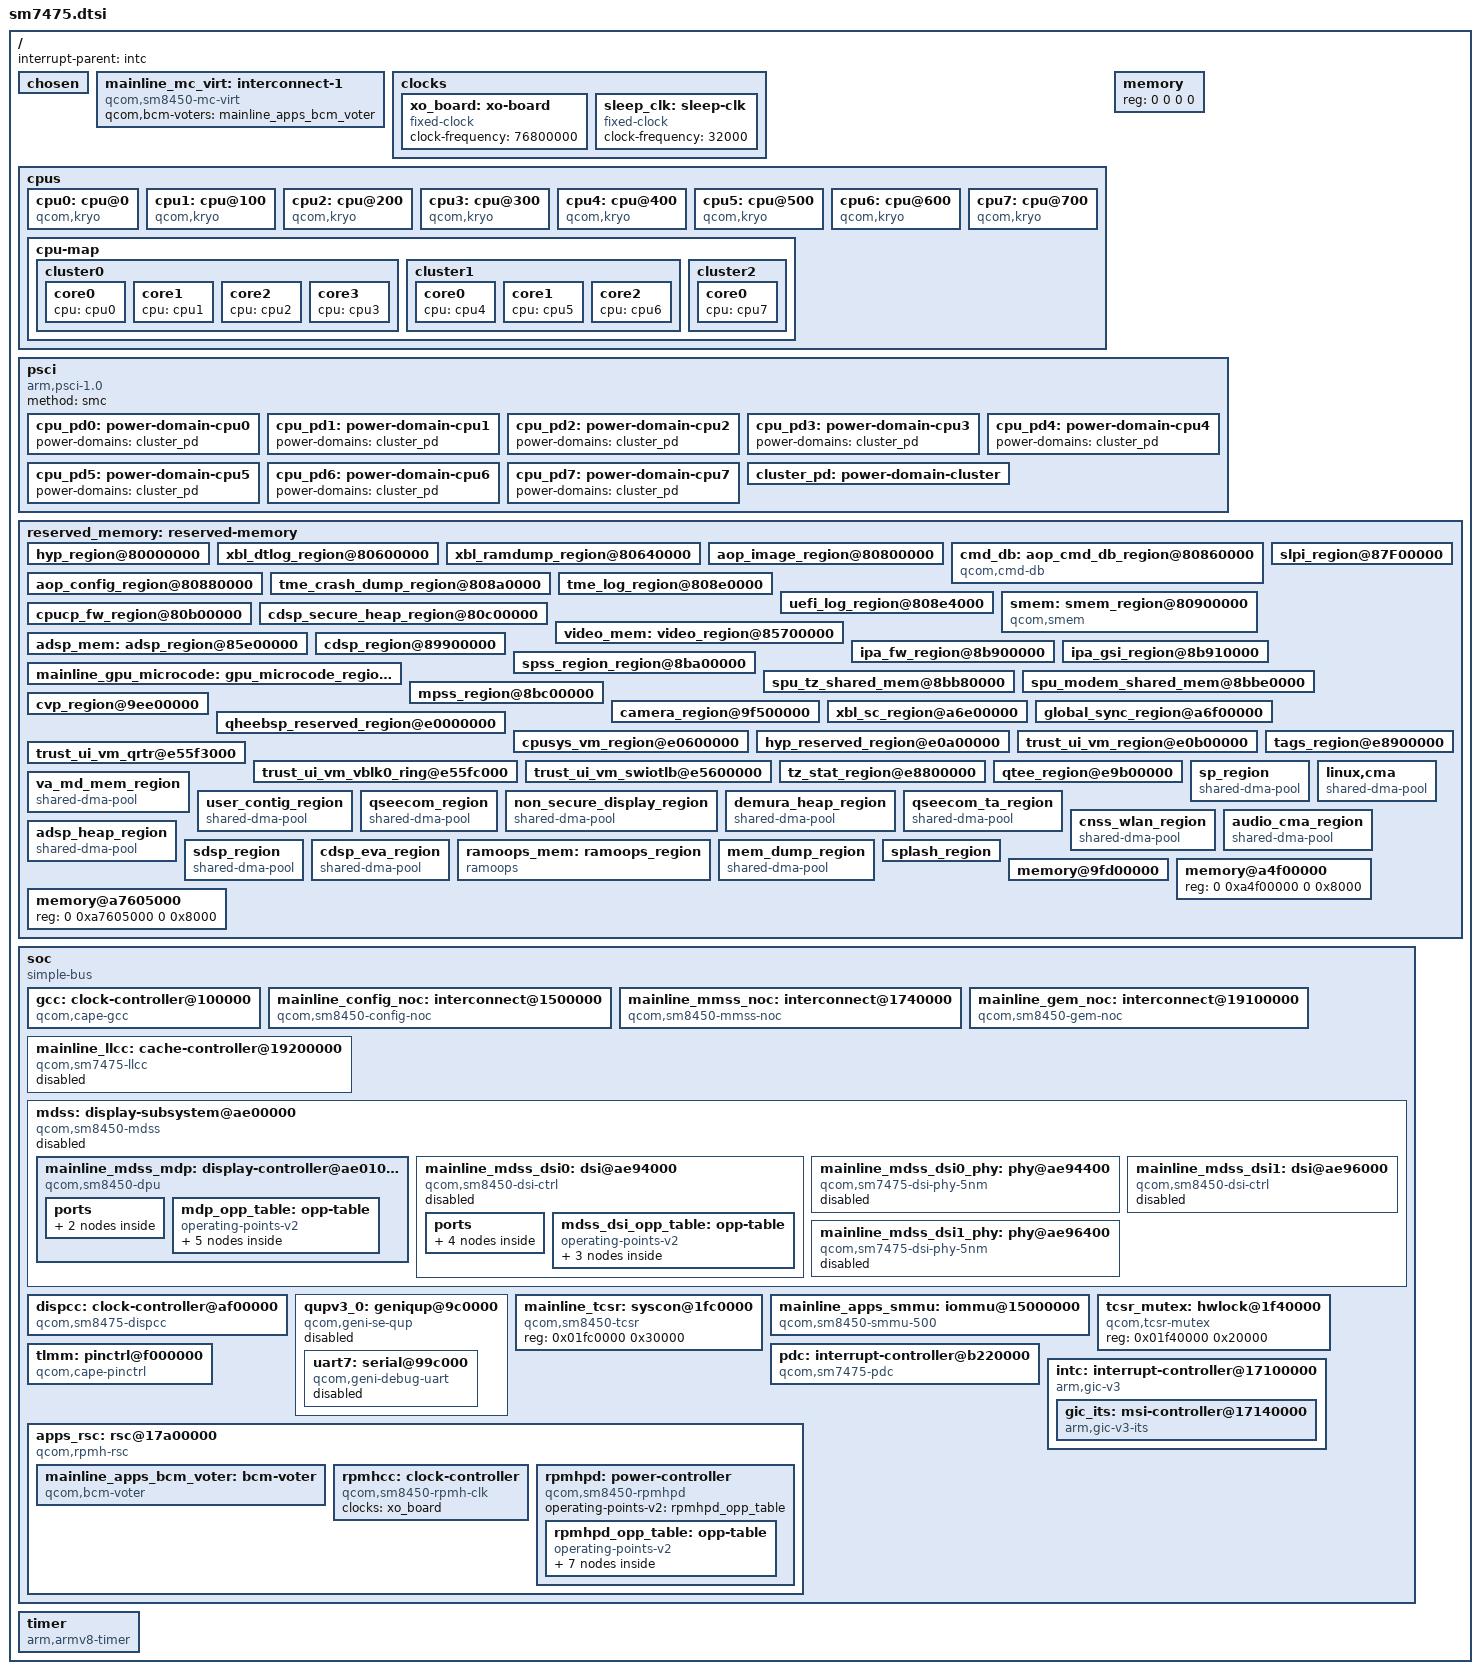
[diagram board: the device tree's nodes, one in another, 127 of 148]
// SPDX-License-Identifier: BSD-3-Clause

#include <dt-bindings/clock/qcom,sm7475-gcc.h>
#include <dt-bindings/clock/qcom,dsi-phy-28nm.h>
#include <dt-bindings/clock/qcom,sm8450-dispcc.h>
#include <dt-bindings/clock/qcom,rpmh.h>
#include <dt-bindings/interconnect/qcom,icc.h>
#include <dt-bindings/interconnect/qcom,sm8450.h>
#include <dt-bindings/interrupt-controller/arm-gic.h>
#include <dt-bindings/power/qcom,rpmhpd.h>
#include <dt-bindings/soc/qcom,rpmh-rsc.h>

/ {
	#address-cells = <2>;
	#size-cells = <2>;
	interrupt-parent = <&intc>;

	chosen { };

	mainline_mc_virt: interconnect-1 {
		compatible = "qcom,sm8450-mc-virt";
		#interconnect-cells = <2>;
		qcom,bcm-voters = <&mainline_apps_bcm_voter>;
	};

	clocks {
		xo_board: xo-board {
			compatible = "fixed-clock";
			#clock-cells = <0>;
			clock-frequency = <76800000>;
		};

		sleep_clk: sleep-clk {
			compatible = "fixed-clock";
			#clock-cells = <0>;
			clock-frequency = <32000>;
		};
	};

	cpus {
		#address-cells = <2>;
		#size-cells = <0>;

		cpu0: cpu@0 {
			compatible = "qcom,kryo";
			device_type = "cpu";
			reg = <0 0x000>;
			enable-method = "psci";
			power-domains = <&cpu_pd0>;
			power-domain-names = "psci";
		};

		cpu1: cpu@100 {
			compatible = "qcom,kryo";
			device_type = "cpu";
			reg = <0 0x100>;
			enable-method = "psci";
			power-domains = <&cpu_pd1>;
			power-domain-names = "psci";
		};

		cpu2: cpu@200 {
			compatible = "qcom,kryo";
			device_type = "cpu";
			reg = <0 0x200>;
			enable-method = "psci";
			power-domains = <&cpu_pd2>;
			power-domain-names = "psci";
		};

		cpu3: cpu@300 {
			compatible = "qcom,kryo";
			device_type = "cpu";
			reg = <0 0x300>;
			enable-method = "psci";
			power-domains = <&cpu_pd3>;
			power-domain-names = "psci";
		};

		cpu4: cpu@400 {
			compatible = "qcom,kryo";
			device_type = "cpu";
			reg = <0 0x400>;
			enable-method = "psci";
			power-domains = <&cpu_pd4>;
			power-domain-names = "psci";
		};

		cpu5: cpu@500 {
			compatible = "qcom,kryo";
			device_type = "cpu";
			reg = <0 0x500>;
			enable-method = "psci";
			power-domains = <&cpu_pd5>;
			power-domain-names = "psci";
		};

		cpu6: cpu@600 {
			compatible = "qcom,kryo";
			device_type = "cpu";
			reg = <0 0x600>;
			enable-method = "psci";
			power-domains = <&cpu_pd6>;
			power-domain-names = "psci";
		};

		cpu7: cpu@700 {
			compatible = "qcom,kryo";
			device_type = "cpu";
			reg = <0 0x700>;
			enable-method = "psci";
			power-domains = <&cpu_pd7>;
			power-domain-names = "psci";
		};

		cpu-map {
			cluster0 {
				core0 { cpu = <&cpu0>; };
				core1 { cpu = <&cpu1>; };
				core2 { cpu = <&cpu2>; };
				core3 { cpu = <&cpu3>; };
			};
			cluster1 {
				core0 { cpu = <&cpu4>; };
				core1 { cpu = <&cpu5>; };
				core2 { cpu = <&cpu6>; };
			};
			cluster2 {
				core0 { cpu = <&cpu7>; };
			};
		};
	};

	/* The Ukee bootloader fills the installed RAM banks. */
	memory {
		device_type = "memory";
		reg = <0 0 0 0>;
	};

	psci {
		compatible = "arm,psci-1.0";
		method = "smc";

		cpu_pd0: power-domain-cpu0 {
			#power-domain-cells = <0>;
			power-domains = <&cluster_pd>;
		};
		cpu_pd1: power-domain-cpu1 {
			#power-domain-cells = <0>;
			power-domains = <&cluster_pd>;
		};
		cpu_pd2: power-domain-cpu2 {
			#power-domain-cells = <0>;
			power-domains = <&cluster_pd>;
		};
		cpu_pd3: power-domain-cpu3 {
			#power-domain-cells = <0>;
			power-domains = <&cluster_pd>;
		};
		cpu_pd4: power-domain-cpu4 {
			#power-domain-cells = <0>;
			power-domains = <&cluster_pd>;
		};
		cpu_pd5: power-domain-cpu5 {
			#power-domain-cells = <0>;
			power-domains = <&cluster_pd>;
		};
		cpu_pd6: power-domain-cpu6 {
			#power-domain-cells = <0>;
			power-domains = <&cluster_pd>;
		};
		cpu_pd7: power-domain-cpu7 {
			#power-domain-cells = <0>;
			power-domains = <&cluster_pd>;
		};
		cluster_pd: power-domain-cluster {
			#power-domain-cells = <0>;
		};
	};

	reserved_memory: reserved-memory {
		#address-cells = <0x02>;
		#size-cells = <0x02>;
		ranges;
		hyp_region@80000000 {
			no-map;
			reg = <0x00 0x80000000 0x00 0x600000>;
		};
		xbl_dtlog_region@80600000 {
			no-map;
			reg = <0x00 0x80600000 0x00 0x40000>;
		};
		xbl_ramdump_region@80640000 {
			no-map;
			reg = <0x00 0x80640000 0x00 0x1c0000>;
		};
		aop_image_region@80800000 {
			no-map;
			reg = <0x00 0x80800000 0x00 0x60000>;
		};
		cmd_db: aop_cmd_db_region@80860000 {
			compatible = "qcom,cmd-db";
			no-map;
			reg = <0x00 0x80860000 0x00 0x20000>;
		};
		aop_config_region@80880000 {
			no-map;
			reg = <0x00 0x80880000 0x00 0x20000>;
		};
		tme_crash_dump_region@808a0000 {
			no-map;
			reg = <0x00 0x808a0000 0x00 0x40000>;
		};
		tme_log_region@808e0000 {
			no-map;
			reg = <0x00 0x808e0000 0x00 0x4000>;
		};
		uefi_log_region@808e4000 {
			no-map;
			reg = <0x00 0x808e4000 0x00 0x10000>;
		};
		smem: smem_region@80900000 {
			compatible = "qcom,smem";
			hwlocks = <&tcsr_mutex 3>;
			no-map;
			reg = <0x00 0x80900000 0x00 0x200000>;
		};
		cpucp_fw_region@80b00000 {
			no-map;
			reg = <0x00 0x80b00000 0x00 0x100000>;
		};
		cdsp_secure_heap_region@80c00000 {
			no-map;
			reg = <0x00 0x80c00000 0x00 0x100000>;
		};
		video_mem: video_region@85700000 {
			no-map;
			reg = <0x00 0x85700000 0x00 0x700000>;
		};
		adsp_mem: adsp_region@85e00000 {
			no-map;
			reg = <0x00 0x85e00000 0x00 0x2100000>;
		};
		slpi_region@87F00000 {
			no-map;
			reg = <0x00 0x87f00000 0x00 0x1a00000>;
		};
		cdsp_region@89900000 {
			no-map;
			reg = <0x00 0x89900000 0x00 0x2000000>;
		};
		ipa_fw_region@8b900000 {
			no-map;
			reg = <0x00 0x8b900000 0x00 0x10000>;
		};
		ipa_gsi_region@8b910000 {
			no-map;
			reg = <0x00 0x8b910000 0x00 0xa000>;
		};
		mainline_gpu_microcode: gpu_microcode_region@8b91a000 {
			no-map;
			reg = <0x00 0x8b91a000 0x00 0x2000>;
		};
		spss_region_region@8ba00000 {
			no-map;
			reg = <0x00 0x8ba00000 0x00 0x180000>;
		};
		spu_tz_shared_mem@8bb80000 {
			no-map;
			reg = <0x00 0x8bb80000 0x00 0x60000>;
		};
		spu_modem_shared_mem@8bbe0000 {
			no-map;
			reg = <0x00 0x8bbe0000 0x00 0x20000>;
		};
		mpss_region@8bc00000 {
			no-map;
			reg = <0x00 0x8bc00000 0x00 0x13200000>;
		};
		cvp_region@9ee00000 {
			no-map;
			reg = <0x00 0x9ee00000 0x00 0x700000>;
		};
		camera_region@9f500000 {
			no-map;
			reg = <0x00 0x9f500000 0x00 0x800000>;
		};
		xbl_sc_region@a6e00000 {
			no-map;
			reg = <0x00 0xa6e00000 0x00 0x40000>;
		};
		global_sync_region@a6f00000 {
			no-map;
			reg = <0x00 0xa6f00000 0x00 0x100000>;
		};
		qheebsp_reserved_region@e0000000 {
			no-map;
			reg = <0x00 0xe0000000 0x00 0x00>;
		};
		cpusys_vm_region@e0600000 {
			no-map;
			reg = <0x00 0xe0600000 0x00 0x400000>;
		};
		hyp_reserved_region@e0a00000 {
			no-map;
			reg = <0x00 0xe0a00000 0x00 0x100000>;
		};
		trust_ui_vm_region@e0b00000 {
			no-map;
			reg = <0x00 0xe0b00000 0x00 0x4af3000>;
		};
		trust_ui_vm_qrtr@e55f3000 {
			no-map;
			reg = <0x00 0xe55f3000 0x00 0x9000>;
		};
		trust_ui_vm_vblk0_ring@e55fc000 {
			no-map;
			reg = <0x00 0xe55fc000 0x00 0x4000>;
			gunyah-label = <0x11>;
		};
		trust_ui_vm_swiotlb@e5600000 {
			no-map;
			reg = <0x00 0xe5600000 0x00 0x100000>;
			gunyah-label = <0x12>;
		};
		tz_stat_region@e8800000 {
			no-map;
			reg = <0x00 0xe8800000 0x00 0x100000>;
		};
		tags_region@e8900000 {
			no-map;
			reg = <0x00 0xe8900000 0x00 0x1200000>;
		};
		qtee_region@e9b00000 {
			no-map;
			reg = <0x00 0xe9b00000 0x00 0x500000>;
		};
		sp_region {
			compatible = "shared-dma-pool";
			alloc-ranges = <0x00 0x00 0x00 0xffffffff>;
			reusable;
			alignment = <0x00 0x400000>;
			size = <0x00 0x1000000>;
		};
		linux,cma {
			compatible = "shared-dma-pool";
			alloc-ranges = <0x00 0x00 0x00 0xffffffff>;
			reusable;
			alignment = <0x00 0x400000>;
			size = <0x00 0x2000000>;
			linux,cma-default;
		};
		va_md_mem_region {
			compatible = "shared-dma-pool";
			alloc-ranges = <0x01 0x00 0xfffffffe 0xffffffff>;
			reusable;
			size = <0x00 0x1000000>;
		};
		user_contig_region {
			compatible = "shared-dma-pool";
			alloc-ranges = <0x00 0x00 0x00 0xffffffff>;
			reusable;
			alignment = <0x00 0x400000>;
			size = <0x00 0x1000000>;
		};
		qseecom_region {
			compatible = "shared-dma-pool";
			alloc-ranges = <0x00 0x00 0x00 0xffffffff>;
			reusable;
			alignment = <0x00 0x400000>;
			size = <0x00 0x4800000>;
		};
		non_secure_display_region {
			compatible = "shared-dma-pool";
			reusable;
			alloc-ranges = <0x00 0x00 0x00 0xffffffff>;
			size = <0x00 0xa400000>;
			alignment = <0x00 0x400000>;
		};
		demura_heap_region {
			compatible = "shared-dma-pool";
			reusable;
			alloc-ranges = <0x01 0x00 0xfffffffe 0xffffffff>;
			size = <0x00 0x2800000>;
			alignment = <0x00 0x400000>;
		};
		qseecom_ta_region {
			compatible = "shared-dma-pool";
			alloc-ranges = <0x00 0x00 0x00 0xffffffff>;
			reusable;
			alignment = <0x00 0x400000>;
			size = <0x00 0x1000000>;
		};
		cnss_wlan_region {
			compatible = "shared-dma-pool";
			alloc-ranges = <0x00 0x00 0x00 0xffffffff>;
			reusable;
			alignment = <0x00 0x400000>;
			size = <0x00 0x2000000>;
		};
		audio_cma_region {
			compatible = "shared-dma-pool";
			alloc-ranges = <0x00 0x00 0x00 0xffffffff>;
			reusable;
			alignment = <0x00 0x400000>;
			size = <0x00 0x1c00000>;
		};
		adsp_heap_region {
			compatible = "shared-dma-pool";
			alloc-ranges = <0x00 0x00 0x00 0xffffffff>;
			reusable;
			alignment = <0x00 0x400000>;
			size = <0x00 0xc00000>;
		};
		sdsp_region {
			compatible = "shared-dma-pool";
			alloc-ranges = <0x00 0x00 0x00 0xffffffff>;
			reusable;
			alignment = <0x00 0x400000>;
			size = <0x00 0x800000>;
		};
		cdsp_eva_region {
			compatible = "shared-dma-pool";
			alloc-ranges = <0x00 0x00 0x00 0xffffffff>;
			reusable;
			alignment = <0x00 0x400000>;
			size = <0x00 0x400000>;
		};
		ramoops_mem: ramoops_region {
			compatible = "ramoops";
			reg = <0x09 0x7a5c0000 0x00 0x00240000>;
			no-map;
			record-size = <0x00080000>;
			console-size = <0x00040000>;
			pmsg-size = <0x00040000>;
			mem-type = <0x02>;
		};
		mem_dump_region {
			compatible = "shared-dma-pool";
			alloc-ranges = <0x01 0x00 0xfffffffe 0xffffffff>;
			reusable;
			alignment = <0x00 0x400000>;
			size = <0x00 0x3000000>;
		};
		/* The bootloader leaves the panel scanout running here; keep it reserved. */
		splash_region {
			no-map;
			reg = <0x00 0xb8000000 0x00 0x2b00000>;
		};
		memory@9fd00000 { reg = <0 0x9fd00000 0 0x700000>; no-map; };
		memory@a4f00000 { reg = <0 0xa4f00000 0 0x8000>; };
		memory@a7605000 { reg = <0 0xa7605000 0 0x8000>; };
	};

	/* The stock base calls this node `soc` - the factory dtbo references that
	 * label - and addresses it with one cell per field (reg = <addr size>).
	 * The bootloader walks this node before the kernel runs, so keep both the
	 * name and the shape; the kernel derives addresses from the parent's cell
	 * count either way. */
	soc: soc {
		compatible = "simple-bus";
		#address-cells = <1>;
		#size-cells = <1>;
		ranges;

		/* Native Cape GCC support is required for the normal UART driver. */
		gcc: clock-controller@100000 {
			compatible = "qcom,cape-gcc";
			reg = <0x00100000 0x1f4200>;
			clocks = <&rpmhcc RPMH_CXO_CLK>, <&sleep_clk>;
			clock-names = "bi_tcxo", "sleep_clk";
			#clock-cells = <1>;
			#reset-cells = <1>;
			#power-domain-cells = <1>;
		};

		/* Waipio NoC resources and addresses match the stock SM7475 DTB. */
		mainline_config_noc: interconnect@1500000 {
			compatible = "qcom,sm8450-config-noc";
			reg = <0x01500000 0x1c000>;
			#interconnect-cells = <2>;
			qcom,bcm-voters = <&mainline_apps_bcm_voter>;
		};

		mainline_mmss_noc: interconnect@1740000 {
			compatible = "qcom,sm8450-mmss-noc";
			reg = <0x01740000 0x1f080>;
			#interconnect-cells = <2>;
			qcom,bcm-voters = <&mainline_apps_bcm_voter>;
		};

		mainline_gem_noc: interconnect@19100000 {
			compatible = "qcom,sm8450-gem-noc";
			reg = <0x19100000 0xbb800>;
			#interconnect-cells = <2>;
			qcom,bcm-voters = <&mainline_apps_bcm_voter>;
		};

		/* Ukee bank windows follow the stock LLCC v2.1 description. */
		mainline_llcc: cache-controller@19200000 {
			compatible = "qcom,sm7475-llcc";
			reg = <0x19200000 0x80000>,
			      <0x19600000 0x80000>,
			      <0x19300000 0x80000>,
			      <0x19700000 0x80000>,
			      <0x19a00000 0x80000>;
			reg-names = "llcc0_base", "llcc1_base", "llcc2_base",
				    "llcc3_base", "llcc_broadcast_base";
			status = "disabled";
		};

		/* Cape uses the SM8450 display register layout. */
		mdss: display-subsystem@ae00000 {
			compatible = "qcom,sm8450-mdss";
			reg = <0x0ae00000 0x1000>;
			reg-names = "mdss";
			/* Both display memory ports share the same Waipio path. */
			interconnects = <&mainline_mmss_noc MASTER_MDP_DISP 0
					 &mainline_mc_virt SLAVE_EBI1_DISP 0>,
					<&mainline_mmss_noc MASTER_MDP_DISP 0
					 &mainline_mc_virt SLAVE_EBI1_DISP 0>,
					<&mainline_gem_noc MASTER_APPSS_PROC
					 QCOM_ICC_TAG_ACTIVE_ONLY
					 &mainline_config_noc SLAVE_DISPLAY_CFG
					 QCOM_ICC_TAG_ACTIVE_ONLY>;
			interconnect-names = "mdp0-mem", "mdp1-mem", "cpu-cfg";
			resets = <&dispcc DISP_CC_MDSS_CORE_BCR>;
			clocks = <&dispcc DISP_CC_MDSS_AHB_CLK>,
				 <&gcc GCC_DISP_HF_AXI_CLK>,
				 <&gcc GCC_DISP_SF_AXI_CLK>,
				 <&dispcc DISP_CC_MDSS_MDP_CLK>;
			iommus = <&mainline_apps_smmu 0x2800 0x402>;
			interrupts = <GIC_SPI 83 IRQ_TYPE_LEVEL_HIGH>;
			interrupt-controller;
			#interrupt-cells = <1>;
			#address-cells = <1>;
			#size-cells = <1>;
			ranges;
			status = "disabled";

			mainline_mdss_mdp: display-controller@ae01000 {
				compatible = "qcom,sm8450-dpu";
				reg = <0x0ae01000 0x8f000>,
				      <0x0aeb0000 0x3000>;
				reg-names = "mdp", "vbif";
				clocks = <&gcc GCC_DISP_HF_AXI_CLK>,
					 <&gcc GCC_DISP_SF_AXI_CLK>,
					 <&dispcc DISP_CC_MDSS_AHB_CLK>,
					 <&dispcc DISP_CC_MDSS_MDP_LUT_CLK>,
					 <&dispcc DISP_CC_MDSS_MDP_CLK>,
					 <&dispcc DISP_CC_MDSS_VSYNC_CLK>;
				clock-names = "bus", "nrt_bus", "iface", "lut", "core", "vsync";
				assigned-clocks = <&dispcc DISP_CC_MDSS_VSYNC_CLK>;
				assigned-clock-rates = <19200000>;
				operating-points-v2 = <&mdp_opp_table>;
				power-domains = <&rpmhpd RPMHPD_MMCX>;
				interrupt-parent = <&mdss>;
				interrupts = <0>;
				ports {
					#address-cells = <1>;
					#size-cells = <0>;
					port@0 {
						reg = <0>;
						dpu_intf1_out: endpoint {
							remote-endpoint = <&mdss_dsi0_in>;
						};
					};
				};

				mdp_opp_table: opp-table {
					compatible = "operating-points-v2";

					opp-172000000 {
						opp-hz = /bits/ 64 <172000000>;
						required-opps = <&rpmhpd_opp_low_svs_d1>;
					};

					opp-200000000 {
						opp-hz = /bits/ 64 <200000000>;
						required-opps = <&rpmhpd_opp_low_svs>;
					};

					opp-325000000 {
						opp-hz = /bits/ 64 <325000000>;
						required-opps = <&rpmhpd_opp_svs>;
					};

					opp-375000000 {
						opp-hz = /bits/ 64 <375000000>;
						required-opps = <&rpmhpd_opp_svs_l1>;
					};

					opp-500000000 {
						opp-hz = /bits/ 64 <500000000>;
						required-opps = <&rpmhpd_opp_nom>;
					};
				};
			};

			mainline_mdss_dsi0: dsi@ae94000 {
				compatible = "qcom,sm8450-dsi-ctrl", "qcom,mdss-dsi-ctrl";
				reg = <0x0ae94000 0x400>;
				reg-names = "dsi_ctrl";
				interrupt-parent = <&mdss>;
				interrupts = <4>;
				clocks = <&dispcc DISP_CC_MDSS_BYTE0_CLK>,
					 <&dispcc DISP_CC_MDSS_BYTE0_INTF_CLK>,
					 <&dispcc DISP_CC_MDSS_PCLK0_CLK>,
					 <&dispcc DISP_CC_MDSS_ESC0_CLK>,
					 <&dispcc DISP_CC_MDSS_AHB_CLK>,
					 <&gcc GCC_DISP_HF_AXI_CLK>;
				clock-names = "byte", "byte_intf", "pixel", "core", "iface", "bus";
				assigned-clocks = <&dispcc DISP_CC_MDSS_BYTE0_CLK_SRC>,
						  <&dispcc DISP_CC_MDSS_PCLK0_CLK_SRC>;
				assigned-clock-parents = <&mainline_mdss_dsi0_phy DSI_BYTE_PLL_CLK>,
							 <&mainline_mdss_dsi0_phy DSI_PIXEL_PLL_CLK>;
				operating-points-v2 = <&mdss_dsi_opp_table>;
				power-domains = <&rpmhpd RPMHPD_MMCX>;
				phys = <&mainline_mdss_dsi0_phy>;
				phy-names = "dsi";
				#address-cells = <1>;
				#size-cells = <0>;
				status = "disabled";
				ports {
					#address-cells = <1>;
					#size-cells = <0>;
					port@0 {
						reg = <0>;
						mdss_dsi0_in: endpoint {
							remote-endpoint = <&dpu_intf1_out>;
						};
					};
					port@1 {
						reg = <1>;
						mdss_dsi0_out: endpoint {
						};
					};
				};

				mdss_dsi_opp_table: opp-table {
					compatible = "operating-points-v2";

					opp-187500000 {
						opp-hz = /bits/ 64 <187500000>;
						required-opps = <&rpmhpd_opp_low_svs>;
					};

					opp-300000000 {
						opp-hz = /bits/ 64 <300000000>;
						required-opps = <&rpmhpd_opp_svs>;
					};

					opp-358000000 {
						opp-hz = /bits/ 64 <358000000>;
						required-opps = <&rpmhpd_opp_svs_l1>;
					};
				};
			};

			mainline_mdss_dsi0_phy: phy@ae94400 {
				compatible = "qcom,sm7475-dsi-phy-5nm";
				reg = <0x0ae94400 0x200>, <0x0ae94600 0x280>,
				      <0x0ae94900 0x260>;
				reg-names = "dsi_phy", "dsi_phy_lane", "dsi_pll";
				#clock-cells = <1>;
				#phy-cells = <0>;
				clocks = <&dispcc DISP_CC_MDSS_AHB_CLK>, <&rpmhcc RPMH_CXO_CLK>;
				clock-names = "iface", "ref";
				status = "disabled";
			};

			mainline_mdss_dsi1: dsi@ae96000 {
				compatible = "qcom,sm8450-dsi-ctrl", "qcom,mdss-dsi-ctrl";
				reg = <0x0ae96000 0x400>;
				reg-names = "dsi_ctrl";
				interrupt-parent = <&mdss>;
				interrupts = <5>;
				clocks = <&dispcc DISP_CC_MDSS_BYTE1_CLK>,
					 <&dispcc DISP_CC_MDSS_BYTE1_INTF_CLK>,
					 <&dispcc DISP_CC_MDSS_PCLK1_CLK>,
					 <&dispcc DISP_CC_MDSS_ESC1_CLK>,
					 <&dispcc DISP_CC_MDSS_AHB_CLK>,
					 <&gcc GCC_DISP_HF_AXI_CLK>;
				clock-names = "byte", "byte_intf", "pixel", "core", "iface", "bus";
				assigned-clocks = <&dispcc DISP_CC_MDSS_BYTE1_CLK_SRC>,
						  <&dispcc DISP_CC_MDSS_PCLK1_CLK_SRC>;
				assigned-clock-parents = <&mainline_mdss_dsi1_phy DSI_BYTE_PLL_CLK>,
							 <&mainline_mdss_dsi1_phy DSI_PIXEL_PLL_CLK>;
				operating-points-v2 = <&mdss_dsi_opp_table>;
				power-domains = <&rpmhpd RPMHPD_MMCX>;
				phys = <&mainline_mdss_dsi1_phy>;
				phy-names = "dsi";
				#address-cells = <1>;
				#size-cells = <0>;
				status = "disabled";
			};

			mainline_mdss_dsi1_phy: phy@ae96400 {
				compatible = "qcom,sm7475-dsi-phy-5nm";
				reg = <0x0ae96400 0x200>, <0x0ae96600 0x280>,
				      <0x0ae96900 0x260>;
				reg-names = "dsi_phy", "dsi_phy_lane", "dsi_pll";
				#clock-cells = <1>;
				#phy-cells = <0>;
				clocks = <&dispcc DISP_CC_MDSS_AHB_CLK>, <&rpmhcc RPMH_CXO_CLK>;
				clock-names = "iface", "ref";
				status = "disabled";
			};
		};

		dispcc: clock-controller@af00000 {
			compatible = "qcom,sm8475-dispcc";
			reg = <0x0af00000 0x20000>;
			clocks = <&rpmhcc RPMH_CXO_CLK>, <&rpmhcc RPMH_CXO_CLK_A>,
				 <&gcc GCC_DISP_AHB_CLK>, <&sleep_clk>,
				 <&mainline_mdss_dsi0_phy DSI_BYTE_PLL_CLK>,
				 <&mainline_mdss_dsi0_phy DSI_PIXEL_PLL_CLK>,
				 <&mainline_mdss_dsi1_phy DSI_BYTE_PLL_CLK>,
				 <&mainline_mdss_dsi1_phy DSI_PIXEL_PLL_CLK>,
				 <0>, <0>, <0>, <0>, <0>, <0>, <0>, <0>;
			power-domains = <&rpmhpd RPMHPD_MMCX>;
			required-opps = <&rpmhpd_opp_low_svs>;
			#clock-cells = <1>;
			#reset-cells = <1>;
			#power-domain-cells = <1>;
			status = "okay";
		};

		qupv3_0: geniqup@9c0000 {
			compatible = "qcom,geni-se-qup";
			reg = <0x009c0000 0x2000>;
			clocks = <&gcc GCC_QUPV3_WRAP_0_M_AHB_CLK>,
				 <&gcc GCC_QUPV3_WRAP_0_S_AHB_CLK>;
			clock-names = "m-ahb", "s-ahb";
			/* SE payload DMA uses this stream; GPI rings use 0x5b6. */
			iommus = <&mainline_apps_smmu 0x5a3 0>;
			#address-cells = <2>;
			#size-cells = <2>;
			ranges;
			status = "disabled";

			uart7: serial@99c000 {
				compatible = "qcom,geni-debug-uart";
				reg = <0 0x0099c000 0 0x4000>;
				interrupts = <GIC_SPI 608 IRQ_TYPE_LEVEL_HIGH>;
				clocks = <&gcc GCC_QUPV3_WRAP0_S7_CLK>;
				clock-names = "se";
				status = "disabled";
			};
		};

		/* Keep factory overlay labels on their sinks; use private labels here. */
		mainline_tcsr: syscon@1fc0000 {
			compatible = "qcom,sm8450-tcsr", "syscon";
			reg = <0x01fc0000 0x30000>;
		};

		mainline_apps_smmu: iommu@15000000 {
			compatible = "qcom,sm8450-smmu-500", "qcom,smmu-500",
				     "arm,mmu-500";
			reg = <0x15000000 0x100000>;
			#iommu-cells = <2>;
			#global-interrupts = <1>;
			interrupts = <GIC_SPI 65 IRQ_TYPE_LEVEL_HIGH>,
				     <GIC_SPI 97 IRQ_TYPE_LEVEL_HIGH>,
				     <GIC_SPI 98 IRQ_TYPE_LEVEL_HIGH>,
				     <GIC_SPI 99 IRQ_TYPE_LEVEL_HIGH>,
				     <GIC_SPI 100 IRQ_TYPE_LEVEL_HIGH>,
				     <GIC_SPI 101 IRQ_TYPE_LEVEL_HIGH>,
				     <GIC_SPI 102 IRQ_TYPE_LEVEL_HIGH>,
				     <GIC_SPI 103 IRQ_TYPE_LEVEL_HIGH>,
				     <GIC_SPI 104 IRQ_TYPE_LEVEL_HIGH>,
				     <GIC_SPI 105 IRQ_TYPE_LEVEL_HIGH>,
				     <GIC_SPI 106 IRQ_TYPE_LEVEL_HIGH>,
				     <GIC_SPI 107 IRQ_TYPE_LEVEL_HIGH>,
				     <GIC_SPI 108 IRQ_TYPE_LEVEL_HIGH>,
				     <GIC_SPI 109 IRQ_TYPE_LEVEL_HIGH>,
				     <GIC_SPI 110 IRQ_TYPE_LEVEL_HIGH>,
				     <GIC_SPI 111 IRQ_TYPE_LEVEL_HIGH>,
				     <GIC_SPI 112 IRQ_TYPE_LEVEL_HIGH>,
				     <GIC_SPI 113 IRQ_TYPE_LEVEL_HIGH>,
				     <GIC_SPI 114 IRQ_TYPE_LEVEL_HIGH>,
				     <GIC_SPI 115 IRQ_TYPE_LEVEL_HIGH>,
				     <GIC_SPI 116 IRQ_TYPE_LEVEL_HIGH>,
				     <GIC_SPI 117 IRQ_TYPE_LEVEL_HIGH>,
				     <GIC_SPI 118 IRQ_TYPE_LEVEL_HIGH>,
				     <GIC_SPI 181 IRQ_TYPE_LEVEL_HIGH>,
				     <GIC_SPI 182 IRQ_TYPE_LEVEL_HIGH>,
				     <GIC_SPI 183 IRQ_TYPE_LEVEL_HIGH>,
				     <GIC_SPI 184 IRQ_TYPE_LEVEL_HIGH>,
				     <GIC_SPI 185 IRQ_TYPE_LEVEL_HIGH>,
				     <GIC_SPI 186 IRQ_TYPE_LEVEL_HIGH>,
				     <GIC_SPI 187 IRQ_TYPE_LEVEL_HIGH>,
				     <GIC_SPI 188 IRQ_TYPE_LEVEL_HIGH>,
				     <GIC_SPI 189 IRQ_TYPE_LEVEL_HIGH>,
				     <GIC_SPI 190 IRQ_TYPE_LEVEL_HIGH>,
				     <GIC_SPI 191 IRQ_TYPE_LEVEL_HIGH>,
				     <GIC_SPI 192 IRQ_TYPE_LEVEL_HIGH>,
				     <GIC_SPI 315 IRQ_TYPE_LEVEL_HIGH>,
				     <GIC_SPI 316 IRQ_TYPE_LEVEL_HIGH>,
				     <GIC_SPI 317 IRQ_TYPE_LEVEL_HIGH>,
				     <GIC_SPI 318 IRQ_TYPE_LEVEL_HIGH>,
				     <GIC_SPI 319 IRQ_TYPE_LEVEL_HIGH>,
				     <GIC_SPI 320 IRQ_TYPE_LEVEL_HIGH>,
				     <GIC_SPI 321 IRQ_TYPE_LEVEL_HIGH>,
				     <GIC_SPI 322 IRQ_TYPE_LEVEL_HIGH>,
				     <GIC_SPI 323 IRQ_TYPE_LEVEL_HIGH>,
				     <GIC_SPI 324 IRQ_TYPE_LEVEL_HIGH>,
				     <GIC_SPI 325 IRQ_TYPE_LEVEL_HIGH>,
				     <GIC_SPI 326 IRQ_TYPE_LEVEL_HIGH>,
				     <GIC_SPI 327 IRQ_TYPE_LEVEL_HIGH>,
				     <GIC_SPI 328 IRQ_TYPE_LEVEL_HIGH>,
				     <GIC_SPI 329 IRQ_TYPE_LEVEL_HIGH>,
				     <GIC_SPI 330 IRQ_TYPE_LEVEL_HIGH>,
				     <GIC_SPI 331 IRQ_TYPE_LEVEL_HIGH>,
				     <GIC_SPI 332 IRQ_TYPE_LEVEL_HIGH>,
				     <GIC_SPI 333 IRQ_TYPE_LEVEL_HIGH>,
				     <GIC_SPI 334 IRQ_TYPE_LEVEL_HIGH>,
				     <GIC_SPI 335 IRQ_TYPE_LEVEL_HIGH>,
				     <GIC_SPI 336 IRQ_TYPE_LEVEL_HIGH>,
				     <GIC_SPI 337 IRQ_TYPE_LEVEL_HIGH>,
				     <GIC_SPI 338 IRQ_TYPE_LEVEL_HIGH>,
				     <GIC_SPI 339 IRQ_TYPE_LEVEL_HIGH>,
				     <GIC_SPI 340 IRQ_TYPE_LEVEL_HIGH>,
				     <GIC_SPI 341 IRQ_TYPE_LEVEL_HIGH>,
				     <GIC_SPI 342 IRQ_TYPE_LEVEL_HIGH>,
				     <GIC_SPI 343 IRQ_TYPE_LEVEL_HIGH>,
				     <GIC_SPI 344 IRQ_TYPE_LEVEL_HIGH>,
				     <GIC_SPI 345 IRQ_TYPE_LEVEL_HIGH>,
				     <GIC_SPI 395 IRQ_TYPE_LEVEL_HIGH>,
				     <GIC_SPI 396 IRQ_TYPE_LEVEL_HIGH>,
				     <GIC_SPI 397 IRQ_TYPE_LEVEL_HIGH>,
				     <GIC_SPI 398 IRQ_TYPE_LEVEL_HIGH>,
				     <GIC_SPI 399 IRQ_TYPE_LEVEL_HIGH>,
				     <GIC_SPI 400 IRQ_TYPE_LEVEL_HIGH>,
				     <GIC_SPI 401 IRQ_TYPE_LEVEL_HIGH>,
				     <GIC_SPI 402 IRQ_TYPE_LEVEL_HIGH>,
				     <GIC_SPI 403 IRQ_TYPE_LEVEL_HIGH>,
				     <GIC_SPI 404 IRQ_TYPE_LEVEL_HIGH>,
				     <GIC_SPI 405 IRQ_TYPE_LEVEL_HIGH>,
				     <GIC_SPI 406 IRQ_TYPE_LEVEL_HIGH>,
				     <GIC_SPI 407 IRQ_TYPE_LEVEL_HIGH>,
				     <GIC_SPI 408 IRQ_TYPE_LEVEL_HIGH>,
				     <GIC_SPI 409 IRQ_TYPE_LEVEL_HIGH>,
				     <GIC_SPI 418 IRQ_TYPE_LEVEL_HIGH>,
				     <GIC_SPI 419 IRQ_TYPE_LEVEL_HIGH>,
				     <GIC_SPI 412 IRQ_TYPE_LEVEL_HIGH>,
				     <GIC_SPI 421 IRQ_TYPE_LEVEL_HIGH>,
				     <GIC_SPI 707 IRQ_TYPE_LEVEL_HIGH>,
				     <GIC_SPI 423 IRQ_TYPE_LEVEL_HIGH>,
				     <GIC_SPI 424 IRQ_TYPE_LEVEL_HIGH>,
				     <GIC_SPI 425 IRQ_TYPE_LEVEL_HIGH>,
				     <GIC_SPI 690 IRQ_TYPE_LEVEL_HIGH>,
				     <GIC_SPI 691 IRQ_TYPE_LEVEL_HIGH>,
				     <GIC_SPI 692 IRQ_TYPE_LEVEL_HIGH>,
				     <GIC_SPI 693 IRQ_TYPE_LEVEL_HIGH>,
				     <GIC_SPI 694 IRQ_TYPE_LEVEL_HIGH>,
				     <GIC_SPI 695 IRQ_TYPE_LEVEL_HIGH>,
				     <GIC_SPI 696 IRQ_TYPE_LEVEL_HIGH>,
				     <GIC_SPI 697 IRQ_TYPE_LEVEL_HIGH>;
			dma-coherent;
		};

		tcsr_mutex: hwlock@1f40000 {
			compatible = "qcom,tcsr-mutex";
			reg = <0x01f40000 0x20000>;
			#hwlock-cells = <1>;
		};

		pdc: interrupt-controller@b220000 {
			compatible = "qcom,sm7475-pdc", "qcom,pdc";
			reg = <0x0b220000 0x30000>,
			      <0x174000f0 0x64>;
			qcom,pdc-ranges = <0 480 94>, <94 609 31>,
					  <125 63 1>, <126 716 12>;
			#interrupt-cells = <2>;
			interrupt-parent = <&intc>;
			interrupt-controller;
		};

		tlmm: pinctrl@f000000 {
			compatible = "qcom,cape-pinctrl";
			reg = <0x0f000000 0x1000000>;
			interrupts = <GIC_SPI 208 IRQ_TYPE_LEVEL_HIGH>;
			gpio-controller;
			#gpio-cells = <2>;
			gpio-ranges = <&tlmm 0 0 211>;
			gpio-reserved-ranges = <28 4>, <36 4>;
			interrupt-controller;
			#interrupt-cells = <2>;
			wakeup-parent = <&pdc>;
		};

		intc: interrupt-controller@17100000 {
			compatible = "arm,gic-v3";
			reg = <0x17100000 0x10000>,
			      <0x17180000 0x200000>;
			interrupt-controller;
			#interrupt-cells = <3>;
			#redistributor-regions = <1>;
			redistributor-stride = <0 0x40000>;
			interrupts = <GIC_PPI 9 IRQ_TYPE_LEVEL_LOW>;
			#address-cells = <2>;
			#size-cells = <2>;
			ranges;

			gic_its: msi-controller@17140000 {
				compatible = "arm,gic-v3-its";
				reg = <0 0x17140000 0 0x20000>;
				msi-controller;
				#msi-cells = <1>;
			};
		};

		apps_rsc: rsc@17a00000 {
			compatible = "qcom,rpmh-rsc";
			label = "apps_rsc";
			reg = <0x17a00000 0x10000>,
			      <0x17a10000 0x10000>,
			      <0x17a20000 0x10000>,
			      <0x17a30000 0x10000>;
			reg-names = "drv-0", "drv-1", "drv-2", "drv-3";
			interrupts = <GIC_SPI 3 IRQ_TYPE_LEVEL_HIGH>,
				     <GIC_SPI 4 IRQ_TYPE_LEVEL_HIGH>,
				     <GIC_SPI 5 IRQ_TYPE_LEVEL_HIGH>;
			qcom,tcs-offset = <0xd00>;
			qcom,drv-id = <2>;
			/* Firmware also defines one type-4 TCS, unused by mainline. */
			qcom,tcs-config = <ACTIVE_TCS 3>, <SLEEP_TCS 2>,
					  <WAKE_TCS 2>, <CONTROL_TCS 0>;
			power-domains = <&cluster_pd>;

			mainline_apps_bcm_voter: bcm-voter {
				compatible = "qcom,bcm-voter";
			};

			rpmhcc: clock-controller {
				/* Waipio RPMh clock resources are shared with SM8450. */
				compatible = "qcom,sm8450-rpmh-clk";
				#clock-cells = <1>;
				clocks = <&xo_board>;
				clock-names = "xo";
			};

			rpmhpd: power-controller {
				compatible = "qcom,sm8450-rpmhpd";
				#power-domain-cells = <1>;
				operating-points-v2 = <&rpmhpd_opp_table>;

				rpmhpd_opp_table: opp-table {
					compatible = "operating-points-v2";

					rpmhpd_opp_ret: opp1 {
						opp-level = <RPMH_REGULATOR_LEVEL_RETENTION>;
					};

					rpmhpd_opp_min_svs: opp2 {
						opp-level = <RPMH_REGULATOR_LEVEL_MIN_SVS>;
					};

					rpmhpd_opp_low_svs_d1: opp3 {
						opp-level = <RPMH_REGULATOR_LEVEL_LOW_SVS_D1>;
					};

					rpmhpd_opp_low_svs: opp4 {
						opp-level = <RPMH_REGULATOR_LEVEL_LOW_SVS>;
					};

					rpmhpd_opp_svs: opp5 {
						opp-level = <RPMH_REGULATOR_LEVEL_SVS>;
					};

					rpmhpd_opp_svs_l1: opp6 {
						opp-level = <RPMH_REGULATOR_LEVEL_SVS_L1>;
					};

					rpmhpd_opp_nom: opp7 {
						opp-level = <RPMH_REGULATOR_LEVEL_NOM>;
					};
				};
			};
		};
	};

	timer {
		compatible = "arm,armv8-timer";
		interrupts = <GIC_PPI 13 IRQ_TYPE_LEVEL_LOW>,
			     <GIC_PPI 14 IRQ_TYPE_LEVEL_LOW>,
			     <GIC_PPI 11 IRQ_TYPE_LEVEL_LOW>,
			     <GIC_PPI 12 IRQ_TYPE_LEVEL_LOW>;
		clock-frequency = <19200000>;
		always-on;
	};
};
